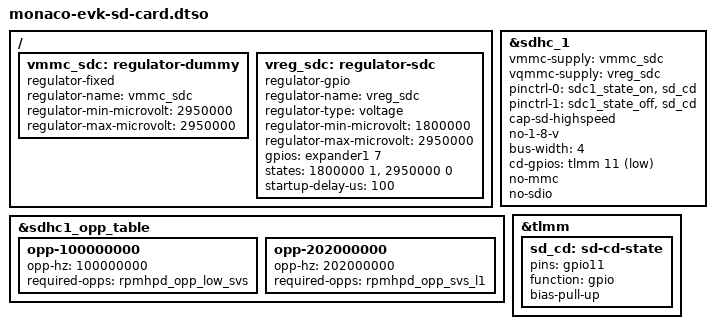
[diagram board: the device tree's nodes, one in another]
// SPDX-License-Identifier: BSD-3-Clause
/*
 * Copyright (c) Qualcomm Technologies, Inc. and/or its subsidiaries.
 */

/dts-v1/;
/plugin/;

#include <dt-bindings/gpio/gpio.h>

/ {
        vmmc_sdc: regulator-dummy {
		compatible = "regulator-fixed";

		regulator-name = "vmmc_sdc";
		regulator-min-microvolt = <2950000>;
		regulator-max-microvolt = <2950000>;
	};

	vreg_sdc: regulator-sdc {
		compatible = "regulator-gpio";

		regulator-name = "vreg_sdc";
		regulator-type = "voltage";
		regulator-min-microvolt = <1800000>;
		regulator-max-microvolt = <2950000>;

		gpios = <&expander1 7 GPIO_ACTIVE_HIGH>;
		states = <1800000 1>, <2950000 0>;

		startup-delay-us = <100>;
	};
};

&sdhc_1 {
	vmmc-supply = <&vmmc_sdc>;
	vqmmc-supply = <&vreg_sdc>;

	pinctrl-0 = <&sdc1_state_on>, <&sd_cd>;
	pinctrl-1 = <&sdc1_state_off>, <&sd_cd>;
	pinctrl-names = "default", "sleep";

	cap-sd-highspeed;
	no-1-8-v;

	bus-width = <4>;
	cd-gpios = <&tlmm 11 GPIO_ACTIVE_LOW>;
	no-mmc;
	no-sdio;

	status = "okay";
};

&sdhc1_opp_table {
	opp-100000000 {
		opp-hz = /bits/ 64 <100000000>;
		required-opps = <&rpmhpd_opp_low_svs>;
	};

	opp-202000000 {
		opp-hz = /bits/ 64 <202000000>;
		required-opps = <&rpmhpd_opp_svs_l1>;
	};
};

&tlmm {
        sd_cd: sd-cd-state {
                pins = "gpio11";
                function = "gpio";
                bias-pull-up;
        };
};
